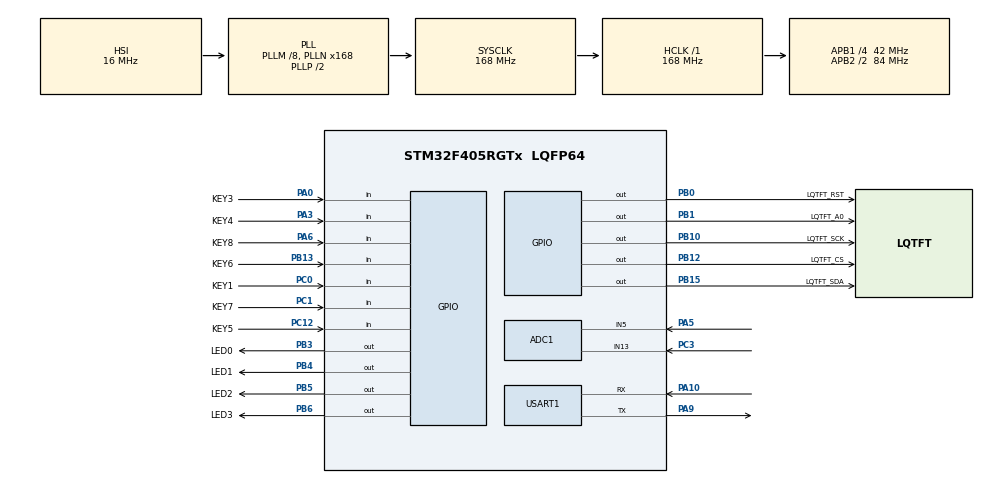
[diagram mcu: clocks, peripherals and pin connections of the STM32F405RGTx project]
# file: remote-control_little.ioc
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Mcu.Family=STM32F4
VP_TIM5_VS_ClockSourceINT.Mode=Internal
PH0-OSC_IN.Signal=RCC_OSC_IN
RCC.CortexFreq_Value=168000000
PB10.GPIO_Speed=GPIO_SPEED_FREQ_HIGH
PB10.GPIO_PuPd=GPIO_PULLUP
ADC1.ContinuousConvMode=ENABLE
PC12.Signal=GPIO_Input
PA3.GPIO_PuPd=GPIO_PULLDOWN
PC0.GPIO_Label=KEY1
PA6.GPIO_Label=KEY8
PB0.GPIO_Label=LQTFT_RST
PB6.GPIO_Label=LED3
PB13.GPIO_Label=KEY6
PB13.Signal=GPIO_Input
PB15.Signal=GPIO_Output
PB3.GPIO_Speed=GPIO_SPEED_FREQ_LOW
RCC.SYSCLKSource=RCC_SYSCLKSOURCE_PLLCLK
ProjectManager.StackSize=0x400
NVIC.TIM5_IRQn=true\:2\:0\:true\:false\:true\:true\:true
PB3.PinState=GPIO_PIN_RESET
PB1.GPIO_PuPd=GPIO_PULLUP
RCC.HCLKFreq_Value=168000000
RCC.APB2TimFreq_Value=168000000
PB6.Signal=GPIO_Output
Dma.ADC1.0.Direction=DMA_PERIPH_TO_MEMORY
PC3.Signal=ADCx_IN13
NVIC.DMA2_Stream0_IRQn=true\:0\:0\:false\:false\:true\:false\:true
Dma.ADC1.0.MemDataAlignment=DMA_MDATAALIGN_HALFWORD
RCC.AHBFreq_Value=168000000
PH0-OSC_IN.Mode=HSE-External-Oscillator
ADC1.Channel-0\#ChannelRegularConversion=ADC_CHANNEL_5
RCC.HSE_VALUE=8000000
PC1.GPIO_PuPd=GPIO_PULLUP
PB12.GPIO_Label=LQTFT_CS
PA6.GPIO_PuPd=GPIO_PULLUP
PB3.GPIO_PuPd=GPIO_PULLUP
PB1.GPIO_Speed=GPIO_SPEED_FREQ_HIGH
PA14.Mode=Serial_Wire
PB1.GPIO_Label=LQTFT_A0
Dma.ADC1.0.PeriphInc=DMA_PINC_DISABLE
ADC1.SamplingTime-0\#ChannelRegularConversion=ADC_SAMPLETIME_480CYCLES
PH1-OSC_OUT.Mode=HSE-External-Oscillator
Mcu.Package=LQFP64
PB1.Signal=GPIO_Output
PA6.Signal=GPIO_Input
PB15.GPIO_PuPd=GPIO_PULLUP
PA10.Signal=USART1_RX
RCC.APB2CLKDivider=RCC_HCLK_DIV2
PB5.GPIO_Label=LED2
RCC.APB1TimFreq_Value=84000000
Dma.ADC1.0.FIFOMode=DMA_FIFOMODE_DISABLE
PC12.GPIO_PuPd=GPIO_PULLUP
PC0.GPIO_PuPd=GPIO_PULLDOWN
NVIC.USART1_IRQn=true\:0\:0\:false\:false\:true\:true\:true
Dma.Request0=ADC1
PB4.Signal=GPIO_Output
PA3.Signal=GPIO_Input
PB3.GPIO_Label=LED0
SH.ADCx_IN13.0=ADC1_IN13,IN13
Dma.ADC1.0.Instance=DMA2_Stream0
ADC1.Rank-0\#ChannelRegularConversion=1
PA10.Mode=Asynchronous
PB6.GPIO_PuPd=GPIO_PULLUP
PC0.Signal=GPIO_Input
RCC.APB1CLKDivider=RCC_HCLK_DIV4
TIM5.AutoReloadPreload=TIM_AUTORELOAD_PRELOAD_ENABLE
PA0-WKUP.GPIO_Label=KEY3
PA0-WKUP.Signal=GPIO_Input
PB0.GPIO_Speed=GPIO_SPEED_FREQ_HIGH
PA13.Signal=SYS_JTMS-SWDIO
Dma.ADC1.0.PeriphDataAlignment=DMA_PDATAALIGN_HALFWORD
PA9.Mode=Asynchronous
ProjectManager.TargetToolchain=STM32CubeIDE
PB10.GPIO_Label=LQTFT_SCK
Dma.ADC1.0.Mode=DMA_CIRCULAR
Dma.ADC1.0.Priority=DMA_PRIORITY_LOW
PA9.Signal=USART1_TX
ADC1.Channel-1\#ChannelRegularConversion=ADC_CHANNEL_13
PB4.GPIO_PuPd=GPIO_PULLUP
RCC.LSE_VALUE=32768
PB12.GPIO_Speed=GPIO_SPEED_FREQ_HIGH
PB10.Signal=GPIO_Output
PA5.Signal=ADCx_IN5
board=custom
RCC.VCOOutputFreq_Value=336000000
PB13.GPIO_PuPd=GPIO_PULLUP
PB4.GPIO_Speed=GPIO_SPEED_FREQ_LOW
RCC.APB2Freq_Value=84000000
PB4.GPIO_Label=LED1
PB15.GPIO_Label=LQTFT_SDA
PB15.GPIO_Speed=GPIO_SPEED_FREQ_HIGH
PC1.GPIO_Label=KEY7
PH1-OSC_OUT.Signal=RCC_OSC_OUT
ADC1.DMAContinuousRequests=ENABLE
ADC1.NbrOfConversion=2
PA13.Mode=Serial_Wire
Mcu.Name=STM32F405RGTx
RCC.48MHZClocksFreq_Value=84000000
PB3.Signal=GPIO_Output
ADC1.SamplingTime-1\#ChannelRegularConversion=ADC_SAMPLETIME_480CYCLES
RCC.SYSCLKFreq_VALUE=168000000
PB5.Signal=GPIO_Output
ADC1.master=1
TIM5.Prescaler=8399
PB5.GPIO_PuPd=GPIO_PULLUP
PC12.GPIO_Label=KEY5
USART1.VirtualMode=VM_ASYNC
ADC1.Rank-1\#ChannelRegularConversion=2
PA14.Signal=SYS_JTCK-SWCLK
Dma.ADC1.0.MemInc=DMA_MINC_ENABLE
ProjectManager.HeapSize=0x200
RCC.HSI_VALUE=16000000
SH.ADCx_IN5.0=ADC1_IN5,IN5
NVIC.PriorityGroup=NVIC_PRIORITYGROUP_4
ADC1.NbrOfConversionFlag=1
RCC.PLLM=8
RCC.PLLN=168
PA0-WKUP.GPIO_PuPd=GPIO_PULLDOWN
TIM5.Period=1999
PB1.GPIO_ModeDefaultOutputPP=GPIO_MODE_OUTPUT_PP
PB12.GPIO_PuPd=GPIO_PULLUP
RCC.APB1Freq_Value=42000000
PB0.Signal=GPIO_Output
PC1.Signal=GPIO_Input
PB12.Signal=GPIO_Output
PB0.GPIO_PuPd=GPIO_PULLUP
PA3.GPIO_Label=KEY4

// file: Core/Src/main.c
/* USER CODE BEGIN Header */
/**
  ******************************************************************************
  * @file           : main.c
  * @brief          : Main program body
  ******************************************************************************
  * @attention
  *
  * <h2><center>&copy; Copyright (c) 2021 STMicroelectronics.
  * All rights reserved.</center></h2>
  *
  * This software component is licensed by ST under BSD 3-Clause license,
  * the "License"; You may not use this file except in compliance with the
  * License. You may obtain a copy of the License at:
  *                        opensource.org/licenses/BSD-3-Clause
  *
  ******************************************************************************
  */
/* USER CODE END Header */
#include "main.h"
#include "adc.h"
#include "dma.h"
#include "tim.h"
#include "usart.h"
#include "gpio.h"

/* USER CODE BEGIN Includes */
#include "key.h"
#include "OLED.h"
/* USER CODE END Includes */

void SystemClock_Config(void);

int main(void)
{

  /* MCU Configuration--------------------------------------------------------*/

  /* Reset of all peripherals, Initializes the Flash interface and the Systick. */
  HAL_Init();

  /* Configure the system clock */
  SystemClock_Config();

  /* Initialize all configured peripherals */
  MX_GPIO_Init();
  MX_DMA_Init();
  MX_TIM5_Init();
  MX_ADC1_Init();
  MX_USART1_UART_Init();
  /* USER CODE BEGIN 2 */
  LCD_init();
//  Show_Start();
  /* USER CODE END 2 */

  /* Infinite loop */
  /* USER CODE BEGIN WHILE */
  while (1)
  {
	  Key_Scan();
    /* USER CODE END WHILE */

  }
}

void SystemClock_Config(void)
{
  RCC_OscInitTypeDef RCC_OscInitStruct = {0};
  RCC_ClkInitTypeDef RCC_ClkInitStruct = {0};

  /** Configure the main internal regulator output voltage
  */
  __HAL_RCC_PWR_CLK_ENABLE();
  __HAL_PWR_VOLTAGESCALING_CONFIG(PWR_REGULATOR_VOLTAGE_SCALE1);
  /** Initializes the RCC Oscillators according to the specified parameters
  * in the RCC_OscInitTypeDef structure.
  */
  RCC_OscInitStruct.OscillatorType = RCC_OSCILLATORTYPE_HSI;
  RCC_OscInitStruct.HSIState = RCC_HSI_ON;
  RCC_OscInitStruct.HSICalibrationValue = RCC_HSICALIBRATION_DEFAULT;
  RCC_OscInitStruct.PLL.PLLState = RCC_PLL_ON;
  RCC_OscInitStruct.PLL.PLLSource = RCC_PLLSOURCE_HSI;
  RCC_OscInitStruct.PLL.PLLM = 8;
  RCC_OscInitStruct.PLL.PLLN = 168;
  RCC_OscInitStruct.PLL.PLLP = RCC_PLLP_DIV2;
  RCC_OscInitStruct.PLL.PLLQ = 4;
  if (HAL_RCC_OscConfig(&RCC_OscInitStruct) != HAL_OK)
  {
    Error_Handler();
  }
  /** Initializes the CPU, AHB and APB buses clocks
  */
  RCC_ClkInitStruct.ClockType = RCC_CLOCKTYPE_HCLK|RCC_CLOCKTYPE_SYSCLK
                              |RCC_CLOCKTYPE_PCLK1|RCC_CLOCKTYPE_PCLK2;
  RCC_ClkInitStruct.SYSCLKSource = RCC_SYSCLKSOURCE_PLLCLK;
  RCC_ClkInitStruct.AHBCLKDivider = RCC_SYSCLK_DIV1;
  RCC_ClkInitStruct.APB1CLKDivider = RCC_HCLK_DIV4;
  RCC_ClkInitStruct.APB2CLKDivider = RCC_HCLK_DIV2;

  if (HAL_RCC_ClockConfig(&RCC_ClkInitStruct, FLASH_LATENCY_5) != HAL_OK)
  {
    Error_Handler();
  }
}

void Error_Handler(void)
{
  __disable_irq();
  while (1)
  {
  }
}

/************************ (C) COPYRIGHT STMicroelectronics *****END OF FILE****/
